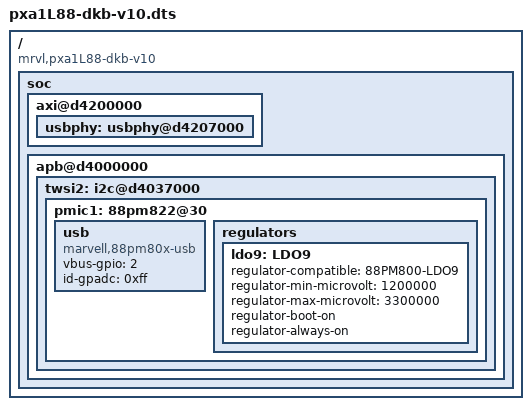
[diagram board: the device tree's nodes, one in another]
/dts-v1/;
#include "pxa1L88-dkb.dtsi"
/ {
	compatible = "mrvl,pxa1L88-dkb-v10", "mrvl,pxa1L88";
	soc {
		axi@d4200000 {	/* AXI */
			usbphy: usbphy@d4207000 {
				status = "okay";
			};
		};
		apb@d4000000 {
			twsi2: i2c@d4037000 {
				pmic1: 88pm822@30 {
					usb: usb {
						compatible = "marvell,88pm80x-usb";
						vbus-gpio = <2>;
						id-gpadc = <0xff>;
					};
					regulators {
						ldo9: LDO9 {
							      regulator-compatible = "88PM800-LDO9";
							      regulator-min-microvolt = <1200000>;
							      regulator-max-microvolt = <3300000>;
							      regulator-boot-on;
							      regulator-always-on;
						};
					};
				};
			};
		};
	};
};
